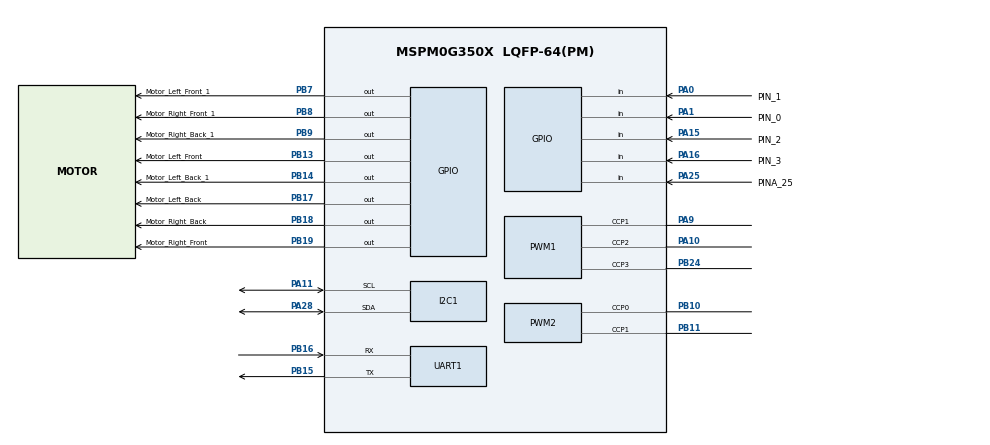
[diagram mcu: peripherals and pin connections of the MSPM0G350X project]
/**
 * @cliArgs --device "MSPM0G350X" --package "LQFP-64(PM)" --part "Default" --product "mspm0_sdk@2.00.01.00"
 * @versions {"tool":"1.19.0+3426"}
 */

/**
 * Import the modules used in this configuration.
 */
const GPIO    = scripting.addModule("/ti/driverlib/GPIO", {}, false);
const GPIO1   = GPIO.addInstance();
const GPIO2   = GPIO.addInstance();
const GPIO3   = GPIO.addInstance();
const GPIO4   = GPIO.addInstance();
const GPIO5   = GPIO.addInstance();
const GPIO6   = GPIO.addInstance();
const I2C     = scripting.addModule("/ti/driverlib/I2C", {}, false);
const I2C1    = I2C.addInstance();
const PWM     = scripting.addModule("/ti/driverlib/PWM", {}, false);
const PWM1    = PWM.addInstance();
const PWM2    = PWM.addInstance();
const SYSCTL  = scripting.addModule("/ti/driverlib/SYSCTL");
const SYSTICK = scripting.addModule("/ti/driverlib/SYSTICK");
const TIMER   = scripting.addModule("/ti/driverlib/TIMER", {}, false);
const TIMER1  = TIMER.addInstance();
const UART    = scripting.addModule("/ti/driverlib/UART", {}, false);
const UART1   = UART.addInstance();

/**
 * Write custom configuration values to the imported modules.
 */
const divider2       = system.clockTree["HFCLK4MFPCLKDIV"];
divider2.divideValue = 2;

const gate7  = system.clockTree["MFCLKGATE"];
gate7.enable = true;

const gate8  = system.clockTree["MFPCLKGATE"];
gate8.enable = true;

const mux10       = system.clockTree["MFPCLKMUX"];
mux10.inputSelect = "MFPCLKMUX_HFCLK";

const pinFunction4     = system.clockTree["HFXT"];
pinFunction4.enable    = true;
pinFunction4.inputFreq = 48;

GPIO1.$name                              = "GPIO_Grayscale";
GPIO1.associatedPins.create(10);
GPIO1.associatedPins[0].initialValue     = "SET";
GPIO1.associatedPins[0].direction        = "INPUT";
GPIO1.associatedPins[0].assignedPort     = "PORTA";
GPIO1.associatedPins[0].assignedPin      = "22";
GPIO1.associatedPins[0].$name            = "PINA_22";
GPIO1.associatedPins[0].internalResistor = "PULL_UP";
GPIO1.associatedPins[1].direction        = "INPUT";
GPIO1.associatedPins[1].assignedPort     = "PORTA";
GPIO1.associatedPins[1].assignedPin      = "24";
GPIO1.associatedPins[1].$name            = "PINA_24";
GPIO1.associatedPins[1].internalResistor = "PULL_UP";
GPIO1.associatedPins[2].direction        = "INPUT";
GPIO1.associatedPins[2].assignedPort     = "PORTA";
GPIO1.associatedPins[2].assignedPin      = "25";
GPIO1.associatedPins[2].$name            = "PINA_25";
GPIO1.associatedPins[2].internalResistor = "PULL_UP";
GPIO1.associatedPins[2].pin.$assign      = "PA25";
GPIO1.associatedPins[3].direction        = "INPUT";
GPIO1.associatedPins[3].assignedPort     = "PORTA";
GPIO1.associatedPins[3].assignedPin      = "26";
GPIO1.associatedPins[3].$name            = "PINA_26";
GPIO1.associatedPins[3].internalResistor = "PULL_UP";
GPIO1.associatedPins[4].direction        = "INPUT";
GPIO1.associatedPins[4].assignedPort     = "PORTA";
GPIO1.associatedPins[4].assignedPin      = "27";
GPIO1.associatedPins[4].$name            = "PINA_27";
GPIO1.associatedPins[4].internalResistor = "PULL_UP";
GPIO1.associatedPins[5].direction        = "INPUT";
GPIO1.associatedPins[5].assignedPort     = "PORTA";
GPIO1.associatedPins[5].assignedPin      = "29";
GPIO1.associatedPins[5].$name            = "PINA_29";
GPIO1.associatedPins[5].internalResistor = "PULL_UP";
GPIO1.associatedPins[6].direction        = "INPUT";
GPIO1.associatedPins[6].assignedPort     = "PORTA";
GPIO1.associatedPins[6].assignedPin      = "30";
GPIO1.associatedPins[6].$name            = "PINA_30";
GPIO1.associatedPins[6].internalResistor = "PULL_UP";
GPIO1.associatedPins[7].direction        = "INPUT";
GPIO1.associatedPins[7].assignedPort     = "PORTA";
GPIO1.associatedPins[7].assignedPin      = "31";
GPIO1.associatedPins[7].$name            = "PINA_31";
GPIO1.associatedPins[7].internalResistor = "PULL_UP";
GPIO1.associatedPins[8].$name            = "PIN_2";
GPIO1.associatedPins[8].initialValue     = "SET";
GPIO1.associatedPins[8].assignedPort     = "PORTA";
GPIO1.associatedPins[8].direction        = "INPUT";
GPIO1.associatedPins[8].internalResistor = "PULL_UP";
GPIO1.associatedPins[8].pin.$assign      = "PA15";
GPIO1.associatedPins[9].$name            = "PIN_3";
GPIO1.associatedPins[9].assignedPort     = "PORTA";
GPIO1.associatedPins[9].direction        = "INPUT";
GPIO1.associatedPins[9].internalResistor = "PULL_UP";
GPIO1.associatedPins[9].pin.$assign      = "PA16";

const Board = scripting.addModule("/ti/driverlib/Board", {}, false);

GPIO2.$name                               = "GPIO_Key";
GPIO2.associatedPins.create(3);
GPIO2.associatedPins[0].$name             = "Key_0";
GPIO2.associatedPins[0].direction         = "INPUT";
GPIO2.associatedPins[0].assignedPort      = "PORTB";
GPIO2.associatedPins[0].assignedPin       = "21";
GPIO2.associatedPins[0].internalResistor  = "PULL_UP";
GPIO2.associatedPins[0].interruptEn       = true;
GPIO2.associatedPins[0].interruptPriority = "1";
GPIO2.associatedPins[0].polarity          = "RISE_FALL";
GPIO2.associatedPins[1].$name             = "Key_1";
GPIO2.associatedPins[1].direction         = "INPUT";
GPIO2.associatedPins[1].assignedPort      = "PORTB";
GPIO2.associatedPins[1].assignedPin       = "23";
GPIO2.associatedPins[1].internalResistor  = "PULL_UP";
GPIO2.associatedPins[1].interruptEn       = true;
GPIO2.associatedPins[1].interruptPriority = "1";
GPIO2.associatedPins[1].polarity          = "RISE_FALL";
GPIO2.associatedPins[2].$name             = "Key_2";
GPIO2.associatedPins[2].direction         = "INPUT";
GPIO2.associatedPins[2].assignedPort      = "PORTB";
GPIO2.associatedPins[2].assignedPin       = "25";
GPIO2.associatedPins[2].internalResistor  = "PULL_UP";
GPIO2.associatedPins[2].interruptEn       = true;
GPIO2.associatedPins[2].interruptPriority = "1";
GPIO2.associatedPins[2].polarity          = "RISE_FALL";

GPIO3.$name                          = "GPIO_LED";
GPIO3.associatedPins[0].assignedPort = "PORTB";
GPIO3.associatedPins[0].assignedPin  = "26";
GPIO3.associatedPins[0].$name        = "Pin_LED";

GPIO4.$name                         = "GPIO_buzzer";
GPIO4.port                          = "PORTB";
GPIO4.associatedPins[0].assignedPin = "27";
GPIO4.associatedPins[0].$name       = "PIN_BUZZER";

GPIO5.$name                          = "GPIO_Motor_Direction";
GPIO5.associatedPins.create(8);
GPIO5.associatedPins[0].assignedPort = "PORTB";
GPIO5.associatedPins[0].$name        = "Motor_Right_Back";
GPIO5.associatedPins[0].ioStructure  = "SD";
GPIO5.associatedPins[0].initialValue = "SET";
GPIO5.associatedPins[0].pin.$assign  = "PB18";
GPIO5.associatedPins[1].assignedPort = "PORTB";
GPIO5.associatedPins[1].$name        = "Motor_Right_Front";
GPIO5.associatedPins[1].initialValue = "SET";
GPIO5.associatedPins[1].pin.$assign  = "PB19";
GPIO5.associatedPins[2].assignedPort = "PORTB";
GPIO5.associatedPins[2].$name        = "Motor_Left_Back";
GPIO5.associatedPins[2].initialValue = "SET";
GPIO5.associatedPins[2].pin.$assign  = "PB17";
GPIO5.associatedPins[3].assignedPort = "PORTB";
GPIO5.associatedPins[3].$name        = "Motor_Left_Front";
GPIO5.associatedPins[3].initialValue = "SET";
GPIO5.associatedPins[3].pin.$assign  = "PB13";
GPIO5.associatedPins[4].$name        = "Motor_Right_Back_1";
GPIO5.associatedPins[4].assignedPort = "PORTB";
GPIO5.associatedPins[4].initialValue = "SET";
GPIO5.associatedPins[4].pin.$assign  = "PB9";
GPIO5.associatedPins[5].$name        = "Motor_Right_Front_1";
GPIO5.associatedPins[5].assignedPort = "PORTB";
GPIO5.associatedPins[5].initialValue = "SET";
GPIO5.associatedPins[5].pin.$assign  = "PB8";
GPIO5.associatedPins[6].$name        = "Motor_Left_Back_1";
GPIO5.associatedPins[6].assignedPort = "PORTB";
GPIO5.associatedPins[6].initialValue = "SET";
GPIO5.associatedPins[6].pin.$assign  = "PB14";
GPIO5.associatedPins[7].$name        = "Motor_Left_Front_1";
GPIO5.associatedPins[7].assignedPort = "PORTB";
GPIO5.associatedPins[7].initialValue = "SET";
GPIO5.associatedPins[7].pin.$assign  = "PB7";

GPIO6.$name                          = "GPIO_GRP_0";
GPIO6.associatedPins.create(2);
GPIO6.associatedPins[0].$name        = "PIN_0";
GPIO6.associatedPins[0].assignedPort = "PORTA";
GPIO6.associatedPins[0].direction    = "INPUT";
GPIO6.associatedPins[0].pin.$assign  = "PA1";
GPIO6.associatedPins[1].$name        = "PIN_1";
GPIO6.associatedPins[1].direction    = "INPUT";
GPIO6.associatedPins[1].pin.$assign  = "PA0";

I2C1.$name                             = "I2C0";
I2C1.basicEnableController             = true;
I2C1.advControllerTXFIFOTRIG           = "BYTES_2";
I2C1.basicControllerStandardBusSpeed   = "FastPlus";
I2C1.enableTimeoutA                    = true;
I2C1.intGeneric                        = ["TIMEOUT_A"];
I2C1.interruptPriority                 = "1";
I2C1.advAnalogGlitchFilter             = "DISABLED";
I2C1.timeoutACount                     = 2;
I2C1.peripheral.$assign                = "I2C0";
I2C1.peripheral.sdaPin.$assign         = "PA28";
I2C1.peripheral.sclPin.$assign         = "PA11";
I2C1.sdaPinConfig.hideOutputInversion  = scripting.forceWrite(false);
I2C1.sdaPinConfig.onlyInternalResistor = scripting.forceWrite(false);
I2C1.sdaPinConfig.passedPeripheralType = scripting.forceWrite("Digital");
I2C1.sdaPinConfig.$name                = "ti_driverlib_gpio_GPIOPinGeneric11";
I2C1.sclPinConfig.hideOutputInversion  = scripting.forceWrite(false);
I2C1.sclPinConfig.onlyInternalResistor = scripting.forceWrite(false);
I2C1.sclPinConfig.passedPeripheralType = scripting.forceWrite("Digital");
I2C1.sclPinConfig.$name                = "ti_driverlib_gpio_GPIOPinGeneric12";

PWM1.ccIndex                            = [1,2,3];
PWM1.timerStartTimer                    = true;
PWM1.timerCount                         = 2000;
PWM1.$name                              = "PWM_Motor_Left";
PWM1.peripheral.$assign                 = "TIMA0";
PWM1.peripheral.ccp1Pin.$assign         = "PA9";
PWM1.peripheral.ccp2Pin.$assign         = "PA10";
PWM1.peripheral.ccp3Pin.$assign         = "PB24";
PWM1.ccp1PinConfig.direction            = scripting.forceWrite("OUTPUT");
PWM1.ccp1PinConfig.hideOutputInversion  = scripting.forceWrite(false);
PWM1.ccp1PinConfig.onlyInternalResistor = scripting.forceWrite(false);
PWM1.ccp1PinConfig.passedPeripheralType = scripting.forceWrite("Digital");
PWM1.ccp1PinConfig.$name                = "ti_driverlib_gpio_GPIOPinGeneric9";
PWM1.ccp1PinConfig.enableConfig         = true;
PWM1.PWM_CHANNEL_2.$name                = "ti_driverlib_pwm_PWMTimerCC2";
PWM1.PWM_CHANNEL_2.dutyCycle            = 25;
PWM1.PWM_CHANNEL_3.$name                = "ti_driverlib_pwm_PWMTimerCC1";
PWM1.PWM_CHANNEL_3.dutyCycle            = 25;
PWM1.ccp2PinConfig.direction            = scripting.forceWrite("OUTPUT");
PWM1.ccp2PinConfig.hideOutputInversion  = scripting.forceWrite(false);
PWM1.ccp2PinConfig.onlyInternalResistor = scripting.forceWrite(false);
PWM1.ccp2PinConfig.passedPeripheralType = scripting.forceWrite("Digital");
PWM1.ccp2PinConfig.$name                = "ti_driverlib_gpio_GPIOPinGeneric10";
PWM1.ccp2PinConfig.enableConfig         = true;
PWM1.ccp3PinConfig.direction            = scripting.forceWrite("OUTPUT");
PWM1.ccp3PinConfig.hideOutputInversion  = scripting.forceWrite(false);
PWM1.ccp3PinConfig.onlyInternalResistor = scripting.forceWrite(false);
PWM1.ccp3PinConfig.passedPeripheralType = scripting.forceWrite("Digital");
PWM1.ccp3PinConfig.$name                = "ti_driverlib_gpio_GPIOPinGeneric8";
PWM1.ccp3PinConfig.enableConfig         = true;
PWM1.PWM_CHANNEL_1.$name                = "ti_driverlib_pwm_PWMTimerCC0";
PWM1.PWM_CHANNEL_1.dutyCycle            = 25;

PWM2.$name                              = "PWM_Motor_Right";
PWM2.timerStartTimer                    = true;
PWM2.timerCount                         = 2000;
PWM2.peripheral.$assign                 = "TIMG6";
PWM2.peripheral.ccp0Pin.$assign         = "PB10";
PWM2.peripheral.ccp1Pin.$assign         = "PB11";
PWM2.PWM_CHANNEL_0.$name                = "ti_driverlib_pwm_PWMTimerCC5";
PWM2.PWM_CHANNEL_0.dutyCycle            = 25;
PWM2.PWM_CHANNEL_1.$name                = "ti_driverlib_pwm_PWMTimerCC6";
PWM2.PWM_CHANNEL_1.dutyCycle            = 25;
PWM2.ccp0PinConfig.direction            = scripting.forceWrite("OUTPUT");
PWM2.ccp0PinConfig.hideOutputInversion  = scripting.forceWrite(false);
PWM2.ccp0PinConfig.onlyInternalResistor = scripting.forceWrite(false);
PWM2.ccp0PinConfig.passedPeripheralType = scripting.forceWrite("Digital");
PWM2.ccp0PinConfig.$name                = "ti_driverlib_gpio_GPIOPinGeneric24";
PWM2.ccp0PinConfig.enableConfig         = true;
PWM2.ccp1PinConfig.direction            = scripting.forceWrite("OUTPUT");
PWM2.ccp1PinConfig.hideOutputInversion  = scripting.forceWrite(false);
PWM2.ccp1PinConfig.onlyInternalResistor = scripting.forceWrite(false);
PWM2.ccp1PinConfig.passedPeripheralType = scripting.forceWrite("Digital");
PWM2.ccp1PinConfig.$name                = "ti_driverlib_gpio_GPIOPinGeneric25";
PWM2.ccp1PinConfig.enableConfig         = true;

SYSCTL.clockTreeEn = true;

SYSTICK.periodEnable      = true;
SYSTICK.interruptEnable   = true;
SYSTICK.systickEnable     = true;
SYSTICK.interruptPriority = "0";
SYSTICK.period            = 32000;

TIMER1.$name              = "TIMER_0";
TIMER1.timerMode          = "PERIODIC";
TIMER1.timerStartTimer    = true;
TIMER1.interrupts         = ["ZERO"];
TIMER1.timerPeriod        = "10ms";
TIMER1.timerClkPrescale   = 200;
TIMER1.interruptPriority  = "1";
TIMER1.peripheral.$assign = "TIMG0";

UART1.$name                            = "UART2";
UART1.enabledInterrupts                = ["RX"];
UART1.targetBaudRate                   = 115200;
UART1.interruptPriority                = "0";
UART1.peripheral.$assign               = "UART2";
UART1.peripheral.rxPin.$assign         = "PB16";
UART1.peripheral.txPin.$assign         = "PB15";
UART1.txPinConfig.direction            = scripting.forceWrite("OUTPUT");
UART1.txPinConfig.hideOutputInversion  = scripting.forceWrite(false);
UART1.txPinConfig.onlyInternalResistor = scripting.forceWrite(false);
UART1.txPinConfig.passedPeripheralType = scripting.forceWrite("Digital");
UART1.txPinConfig.$name                = "ti_driverlib_gpio_GPIOPinGeneric4";
UART1.txPinConfig.enableConfig         = true;
UART1.rxPinConfig.hideOutputInversion  = scripting.forceWrite(false);
UART1.rxPinConfig.onlyInternalResistor = scripting.forceWrite(false);
UART1.rxPinConfig.passedPeripheralType = scripting.forceWrite("Digital");
UART1.rxPinConfig.$name                = "ti_driverlib_gpio_GPIOPinGeneric5";
UART1.rxPinConfig.enableConfig         = true;
UART1.rxPinConfig.internalResistor     = "PULL_UP";

/**
 * Pinmux solution for unlocked pins/peripherals. This ensures that minor changes to the automatic solver in a future
 * version of the tool will not impact the pinmux you originally saw.  These lines can be completely deleted in order to
 * re-solve from scratch.
 */
pinFunction4.peripheral.$suggestSolution           = "SYSCTL";
pinFunction4.peripheral.hfxInPin.$suggestSolution  = "PA5";
pinFunction4.peripheral.hfxOutPin.$suggestSolution = "PA6";
GPIO1.associatedPins[0].pin.$suggestSolution       = "PA22";
GPIO1.associatedPins[1].pin.$suggestSolution       = "PA24";
GPIO1.associatedPins[3].pin.$suggestSolution       = "PA26";
GPIO1.associatedPins[4].pin.$suggestSolution       = "PA27";
GPIO1.associatedPins[5].pin.$suggestSolution       = "PA29";
GPIO1.associatedPins[6].pin.$suggestSolution       = "PA30";
GPIO1.associatedPins[7].pin.$suggestSolution       = "PA31";
Board.peripheral.$suggestSolution                  = "DEBUGSS";
Board.peripheral.swclkPin.$suggestSolution         = "PA20";
Board.peripheral.swdioPin.$suggestSolution         = "PA19";
GPIO2.associatedPins[0].pin.$suggestSolution       = "PB21";
GPIO2.associatedPins[1].pin.$suggestSolution       = "PB23";
GPIO2.associatedPins[2].pin.$suggestSolution       = "PB25";
GPIO3.associatedPins[0].pin.$suggestSolution       = "PB26";
GPIO4.associatedPins[0].pin.$suggestSolution       = "PB27";
